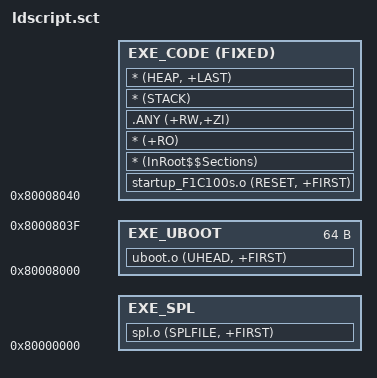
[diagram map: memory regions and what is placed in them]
;// 本文件由洪旭耀设计，可以通过QQ联系作者：26750452

;// 最大16KB，TTB放在0x80004000处
FLASH_SPL 0x80000000 0x4000
{
  EXE_SPL +0
  {
    spl.o (SPLFILE, +FIRST)
  }
}

FLASH_APP 0x80008000 0x1000000
{
  EXE_UBOOT 0x80008000 0x40
  {
    uboot.o (UHEAD, +FIRST)
  }
  EXE_CODE 0x80008040 FIXED
  {
    startup_F1C100s.o (RESET, +FIRST)
    * (InRoot$$Sections)
    * (+RO)
    .ANY (+RW,+ZI)
    * (STACK)
    * (HEAP, +LAST)
  }
}

